# cxd5602 register map
Vendor: Sony Semiconductor Solutions; Series: CXD56xx; File version: 1.0
ARM 32-bit Cortex-M4F Microcontroller based device, CPU clock up to 156MHz, etc.
CPU: CM4 r0p1, little endian, MPU, FPU, 3 interrupt priority bits, 144 interrupts
Registers are 32-bit, read-write, reset 0x0 unless marked. A register's access mark holds for its fields unless they carry their own. Offsets are from the block's base; lines under a group give offsets from that group; [hi:lo] are bit positions; {n}, {i} and the like mark numbered series; 'fields as' and 'values as' point back to an identical list; <NAME> marks a mode.

## Memory map
0x02001000 SMP_RAM_CTRL size 0x1000 — SRAM Control
0x02011000 CRG size 0x1000 — Clock / Reset / Gating
0x02012000 ADDRCONV size 0x1000 — Address Converter
0x02020000 DMAC1 size 0x1000 — DMA controller (ADMAC)
0x02100000 CISIF size 0x1000 — CMOS Image Sensor IF
0x02101000 GE2D size 0x400 — Hardware 2D Graphics Engine
0x02101400 ROT size 0x400 — Image rotation
0x02102000 DMAC3 size 0x1000 — DMA controller (IDMAC)
0x02103000 UART2 size 0x400 — UART
0x02103400 SPI4 size 0x400 — Synchronous Serial Port Controller (IMG SPI)
0x02103C00 SPI5 size 0x400 — Synchronous Serial Port Controller (IMG WSPI)
0x0418D000 SPI3 size 0x1000 — Synchronous Serial Port Controller (SCU SPI)
0x041AA000 SPI0 size 0x1000 — Synchronous Serial Port Controller (SPIM)
0x041AC000 UART1 size 0x400 — UART
0x4600C400 CPU_FIFO size 0x20 — CPU FIFO Control

## Interrupts
1 CRG — CRG interrupt
27 UART1 — UART1 interrupt
32 SPI3 — SPI3 interrupt
90 SPI0 — SPI0 interrupt
106 2D (GE2D) — 2D interrupt
107 ROT — Rotation interrupt
124 CISIF — CISIF interrupt
125 SPI5 — SPI5 interrupt
126 DMAC3 — DMAC3 interrupt
127 UART2 — UART2 interrupt
129 SPI4 — SPI4 interrupt
134 DMAC1 — DMAC1 interrupt

## SMP_RAM_CTRL — SRAM Control
Base 0x02001000
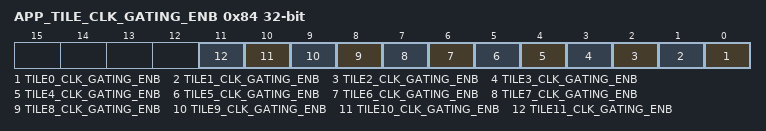
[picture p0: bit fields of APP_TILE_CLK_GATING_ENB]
0x84 APP_TILE_CLK_GATING_ENB (reset mask 0xFFF) — SRAM tile (128KB) clock gating control (0 = gated)
  [n] TILE{n}_CLK_GATING_ENB (n=0..11) — Enable clock gating
    0=gated; 1=ungated

## CRG — Clock / Reset / Gating
Base 0x02011000
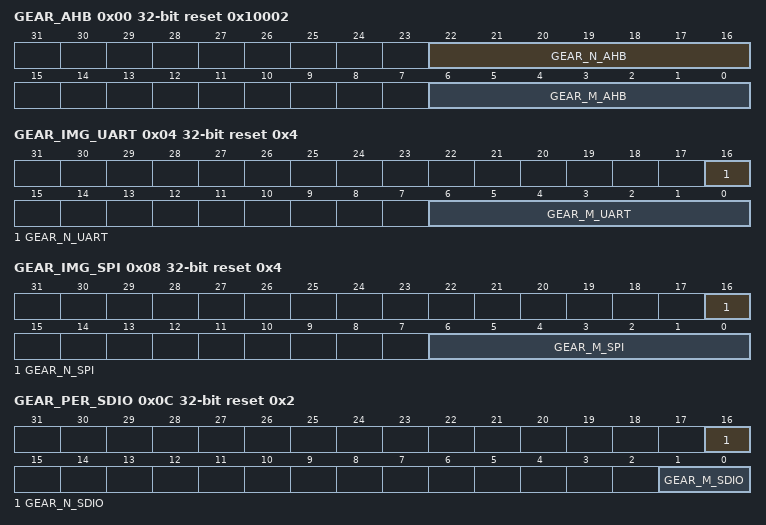
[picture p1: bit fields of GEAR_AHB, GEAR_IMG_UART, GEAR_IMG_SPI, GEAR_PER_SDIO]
0x00 GEAR_AHB reset 0x10002 — Gear ratio (n/m) for AHB
  [22:16] GEAR_N_AHB, [6:0] GEAR_M_AHB
0x04 GEAR_IMG_UART reset 0x4 — IMG UART clock setting
  [16] GEAR_N_UART, [6:0] GEAR_M_UART
0x08 GEAR_IMG_SPI reset 0x4 — IMG SPI clock setting
  [16] GEAR_N_SPI, [6:0] GEAR_M_SPI
0x0C GEAR_PER_SDIO reset 0x2 — SDIO clock setting
  [16] GEAR_N_SDIO, [1:0] GEAR_M_SDIO
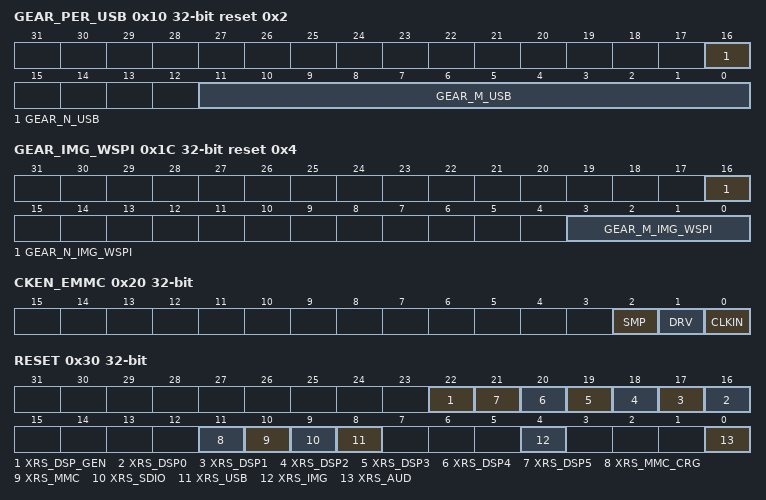
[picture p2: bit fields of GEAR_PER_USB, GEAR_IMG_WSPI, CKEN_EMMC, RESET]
0x10 GEAR_PER_USB reset 0x2 — USB clock setting
  [16] GEAR_N_USB, [11:0] GEAR_M_USB
0x14 GEAR_M_IMG_VENB — VENB_M clock setting
0x18 GEAR_N_IMG_VENB — VENB_N clock setting
0x1C GEAR_IMG_WSPI reset 0x4 — IMG WSPI clock setting
  [16] GEAR_N_IMG_WSPI, [3:0] GEAR_M_IMG_WSPI
0x20 CKEN_EMMC — eMMC clock setting
  [all] fields
    0=DISABLE; 1=ENABLE
  [2] SMP — Enable eMMC sampling clock
  [1] DRV — Enable DRV clock
  [0] CLKIN — Enable eMMC clock
0x30 RESET — Reset control
  [all] fields
    0=RESET; 1=ACTIVE
  [22] XRS_DSP_GEN — 0=reset, 1=active
  [n+16] XRS_DSP{n} (n=0..5) — 0=reset, 1=active
  [11] XRS_MMC_CRG — 0=reset, 1=active
  [10] XRS_MMC — 0=reset, 1=active
  [9] XRS_SDIO — 0=reset, 1=active
  [8] XRS_USB — 0=reset, 1=active
  [4] XRS_IMG — 0=reset, 1=active
  [0] XRS_AUD — 0=reset, 1=active
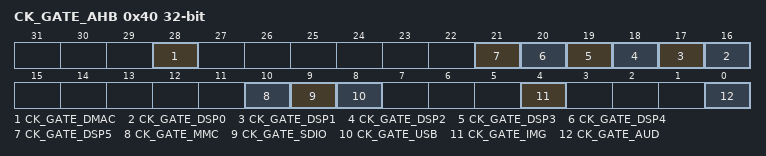
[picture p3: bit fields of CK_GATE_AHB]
0x40 CK_GATE_AHB — CPU/Peripheral clock gating control
  [all] fields
    0=GATED; 1=UNGATED
  [28] CK_GATE_DMAC — 0=Gated, 1=Ungated
  [n+16] CK_GATE_DSP{n} (n=0..5) — 0=Gated, 1=Ungated
  [10] CK_GATE_MMC — 0=Gated, 1=Ungated
  [9] CK_GATE_SDIO — 0=Gated, 1=Ungated
  [8] CK_GATE_USB — 0=Gated, 1=Ungated
  [4] CK_GATE_IMG — 0=Gated, 1=Ungated
  [0] CK_GATE_AUD — 0=Gated, 1=Ungated

## Licence text in the file
Copyright 2019 Sony Semiconductor Solutions Corporation . Redistribution and use in source and binary forms, with or without modification, are permitted provided that the following conditions are met: . 1. Redistributions of source code must retain the above copyright notice, this list of conditions and the following disclaimer. 2. Redistributions in binary form must reproduce the above copyright notice, this list of conditions and the following disclaimer in the documentation and/or other materials provided with the distribution. 3. Neither the name of Sony Semiconductor Solutions Corporation nor the names of its contributors may be used to endorse or promote products derived from this software without specific prior written permission. . THIS SOFTWARE IS PROVIDED BY THE COPYRIGHT HOLDERS AND CONTRIBUTORS "AS IS" AND ANY EXPRESS OR IMPLIED WARRANTIES, INCLUDING, BUT NOT. LIMITED TO, THE IMPLIED WARRANTIES OF MERCHANTABILITY AND FITNESS. FOR A PARTICULAR PURPOSE ARE DISCLAIMED. IN NO EVENT SHALL THE. COPYRIGHT OWNER OR CONTRIBUTORS BE LIABLE FOR ANY DIRECT, INDIRECT, INCIDENTAL, SPECIAL, EXEMPLARY, OR CONSEQUENTIAL DAMAGES (INCLUDING, BUT NOT LIMITED TO, PROCUREMENT OF SUBSTITUTE GOODS OR SERVICES; LOSS. OF USE, DATA, OR PROFITS; OR BUSINESS INTERRUPTION) HOWEVER CAUSED. AND ON ANY THEORY OF LIABILITY, WHETHER IN CONTRACT, STRICT. LIABILITY, OR TORT (INCLUDING NEGLIGENCE OR OTHERWISE) ARISING IN. ANY WAY OUT OF THE USE OF THIS SOFTWARE, EVEN IF ADVISED OF THE. POSSIBILITY OF SUCH DAMAGE.
